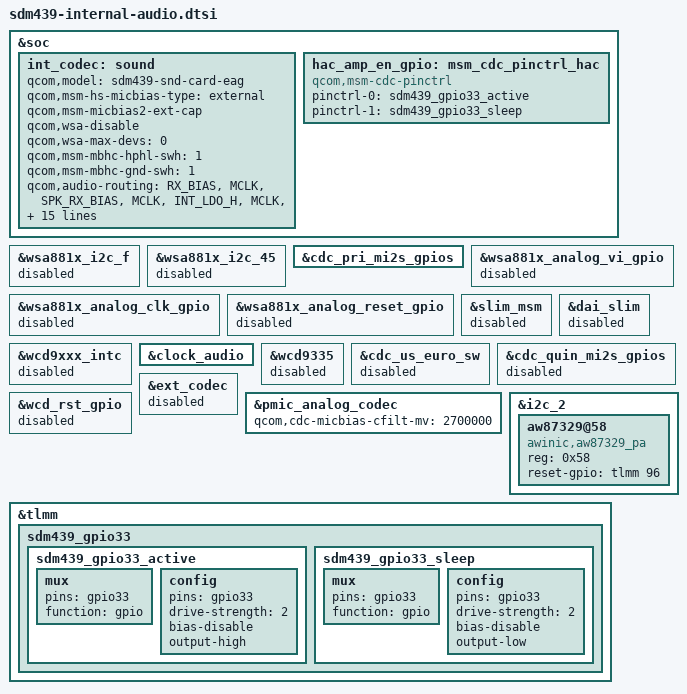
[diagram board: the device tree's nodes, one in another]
/*
 * Copyright (c) 2018, The Linux Foundation. All rights reserved.
 *
 * This program is free software; you can redistribute it and/or modify
 * it under the terms of the GNU General Public License version 2 and
 * only version 2 as published by the Free Software Foundation.
 *
 * This program is distributed in the hope that it will be useful,
 * but WITHOUT ANY WARRANTY; without even the implied warranty of
 * MERCHANTABILITY or FITNESS FOR A PARTICULAR PURPOSE.  See the
 * GNU General Public License for more details.
 */
&soc {
        int_codec: sound {
	    status = "ok";
            qcom,model = "sdm439-snd-card-eag";
            qcom,msm-hs-micbias-type = "external";
            qcom,msm-micbias2-ext-cap;
            qcom,wsa-disable;
            qcom,wsa-max-devs = <0>;
            /delete-property/ qcom,wsa-devs;
            /delete-property/ qcom,wsa-aux-dev-prefix;
            /delete-property/ msm-vdd-wsa-switch-supply;
            /delete-property/ qcom,msm-vdd-wsa-switch-voltage;
            /delete-property/ qcom,msm-vdd-wsa-switch-current;
            /delete-property/ qcom,cdc-us-euro-gpios;
            /delete-property/ qcom,cdc-us-eu-gpios;
            /delete-property/ asoc-wsa-codec-names;
            /delete-property/ asoc-wsa-codec-prefixes;
            qcom,msm-mbhc-hphl-swh = <1>;
            qcom,msm-mbhc-gnd-swh = <1>;
            qcom,audio-routing =
                    "RX_BIAS", "MCLK",
                    "SPK_RX_BIAS", "MCLK",
                    "INT_LDO_H", "MCLK",
                    "RX_I2S_CLK", "MCLK",
                    "TX_I2S_CLK", "MCLK",
                    "MIC BIAS External", "Handset Mic",
                    "MIC BIAS External2", "Headset Mic",
                    "MIC BIAS External", "Secondary Mic",
                    "AMIC1", "MIC BIAS External",
                    "AMIC2", "MIC BIAS External2",
                    "AMIC3", "MIC BIAS External",
                    "ADC1_IN", "ADC1_OUT",
                    "ADC2_IN", "ADC2_OUT",
                    "ADC3_IN", "ADC3_OUT",
                    "PDM_IN_RX1", "PDM_OUT_RX1",
                    "PDM_IN_RX2", "PDM_OUT_RX2",
                    "PDM_IN_RX3", "PDM_OUT_RX3";

            fih,hac-amp-en-gpio = <&hac_amp_en_gpio>;
            fih,fih-mbhc-customized-debounce-supported = <9>;
            fih,msm-hs-v-headset-max = <1500>;
            fih,msm-btn-vol-thr-low = <100 225 400 400 400>;
            fih,msm-btn-vol-thr-high = <112 250 437 437 437>;
      };

};

&wsa881x_i2c_f {
	status = "disabled";
};

&wsa881x_i2c_45 {
	status = "disabled";
};

&cdc_pri_mi2s_gpios {
	status = "okay";
};

&wsa881x_analog_vi_gpio {
	status = "disabled";
};

&wsa881x_analog_clk_gpio {
	status = "disabled";
};

&wsa881x_analog_reset_gpio {
	status = "disabled";
};

&slim_msm {
	status = "disabled";
};

&dai_slim {
	status = "disabled";
};

&wcd9xxx_intc {
	status = "disabled";
};

&clock_audio {
	status = "okay";
};

&wcd9335 {
	status = "disabled";
};

&cdc_us_euro_sw {
	status = "disabled";
};

&cdc_quin_mi2s_gpios {
	status = "disabled";
};

&wcd_rst_gpio {
	status = "disabled";
};

&ext_codec {
	status = "disabled";
};

&pmic_analog_codec {
	status = "okay";
        qcom,cdc-micbias-cfilt-mv = <2700000>;
};

&i2c_2 {
  status = "ok";
  aw87329@58 {
      compatible = "awinic,aw87329_pa";
      reg = <0x58>;
      reset-gpio = <&tlmm 96 0>;
      status = "okay";
  };
};

/* HAC */
&soc {
        hac_amp_en_gpio: msm_cdc_pinctrl_hac {
                compatible = "qcom,msm-cdc-pinctrl";
                pinctrl-names = "aud_active", "aud_sleep";
                pinctrl-0 = <&sdm439_gpio33_active>;
                pinctrl-1 = <&sdm439_gpio33_sleep>;
        };
};



/* gpio */
&tlmm {
    sdm439_gpio33 { /* HAC_AMP_EN */
        sdm439_gpio33_active: sdm439_gpio33_active {
            mux {
                pins = "gpio33";
                function = "gpio";
            };

            config {
                pins = "gpio33";
                drive-strength = <2>;
                bias-disable;
                output-high;
            };
        };

        sdm439_gpio33_sleep: sdm439_gpio33_sleep {
            mux {
                pins = "gpio33";
                function = "gpio";
            };

            config {
                pins = "gpio33";
                drive-strength = <2>;
                bias-disable;
                output-low;
            };
        };
    };
};
